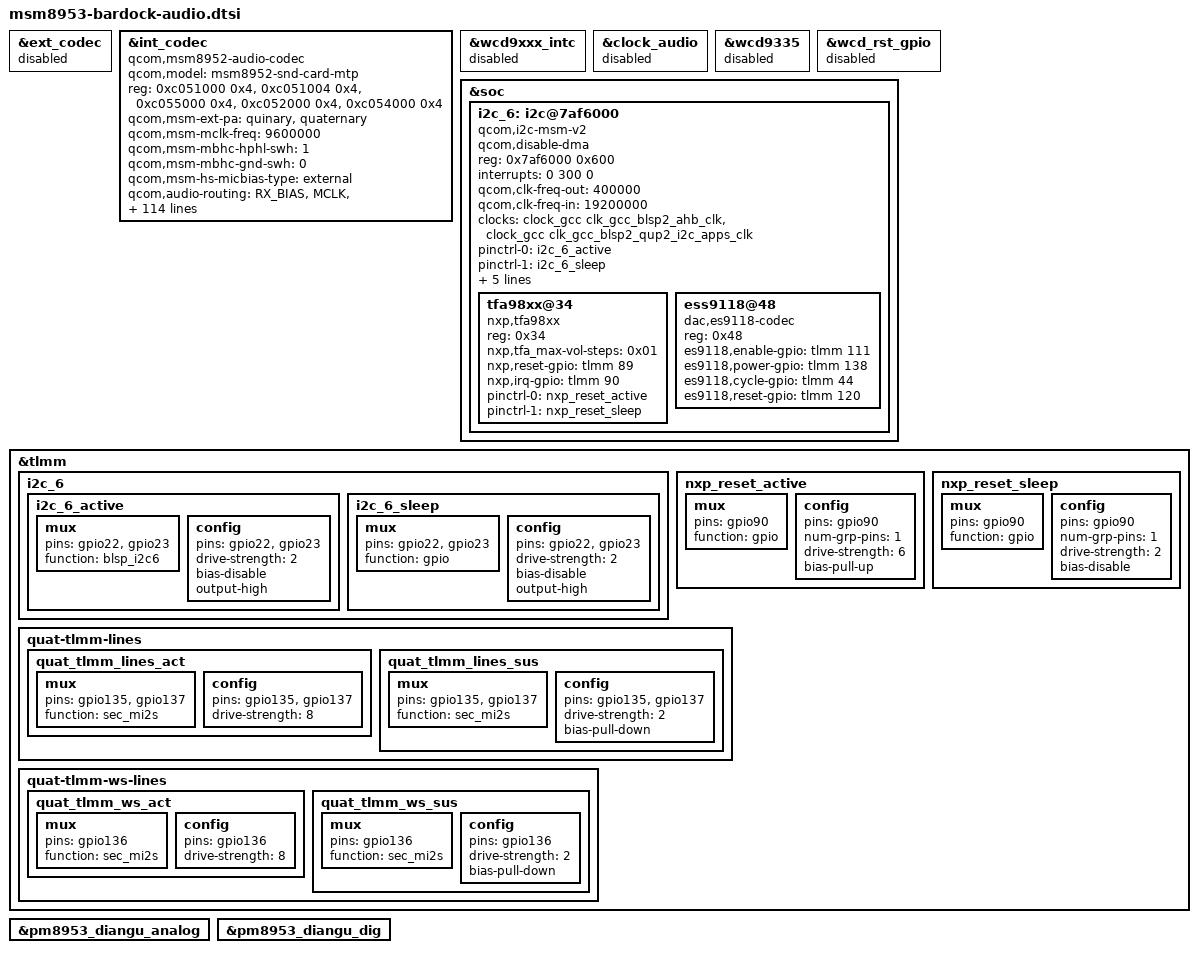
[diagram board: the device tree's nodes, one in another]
/*
 * Copyright (c) 2018, The LineageOS Project. All rights reserved.
 *
 * This program is free software; you can redistribute it and/or modify
 * it under the terms of the GNU General Public License version 2 and
 * only version 2 as published by the Free Software Foundation.
 *
 * This program is distributed in the hope that it will be useful,
 * but WITHOUT ANY WARRANTY; without even the implied warranty of
 * MERCHANTABILITY or FITNESS FOR A PARTICULAR PURPOSE.  See the
 * GNU General Public License for more details.
 */

&ext_codec {
	status = "disabled";
};

&int_codec {
	status = "ok";
	compatible = "qcom,msm8952-audio-codec";
	qcom,model = "msm8952-snd-card-mtp";

	/delete-property/ qcom,cdc-us-euro-gpios;

	reg =   <0xc051000 0x4>,
		<0xc051004 0x4>,
		<0xc055000 0x4>,
		<0xc052000 0x4>,
		<0xc054000 0x4>;
	reg-names = "csr_gp_io_mux_mic_ctl",
		"csr_gp_io_mux_spkr_ctl",
		"csr_gp_io_lpaif_pri_pcm_pri_mode_muxsel",
		"csr_gp_io_mux_quin_ctl",
		"csr_gp_io_mux_mic_ext_clk_ctl";

	qcom,msm-ext-pa = "quinary","quaternary";
	qcom,msm-mclk-freq = <9600000>;
	qcom,msm-mbhc-hphl-swh = <1>;
	qcom,msm-mbhc-gnd-swh = <0>;
	qcom,msm-hs-micbias-type = "external";

	qcom,audio-routing =
		"RX_BIAS", "MCLK",
		"SPK_RX_BIAS", "MCLK",
		"INT_LDO_H", "MCLK",
		"MIC BIAS External", "Handset Mic",
		"MIC BIAS External2", "Headset Mic",
		"MIC BIAS External", "Secondary Mic",
		"AMIC1", "MIC BIAS External",
		"AMIC2", "MIC BIAS External2",
		"AMIC3", "MIC BIAS External";
	qcom,msm-gpios = 
		"pri_i2s", 
		"us_eu_gpio", 
		"quin_i2s", 
		"quat_i2s"; 
	qcom,pinctrl-names = 
		"all_off", 
		"pri_i2s_act", 
		"us_eu_gpio_act", 
		"pri_i2s_us_eu_gpio_act", 
		"quin_act", 
		"quin_pri_i2s_act", 
		"quin_us_eu_gpio_act", 
		"quin_us_eu_gpio_pri_i2s_act", 
		"quat_i2s_act", 
		"quat_pri_i2s_act", 
		"quat_us_eu_gpio_act", 
		"quat_pri_i2s_us_eu_gpio_act", 
		"quat_quin_act", 
		"quat_quin_pri_i2s_act", 
		"quat_quin_us_eu_gpio_act", 
		"quat_quin_us_eu_gpio_pri_i2s_act"; 
	pinctrl-names = 
		"all_off", 
		"pri_i2s_act", 
		"us_eu_gpio_act", 
		"pri_i2s_us_eu_gpio_act", 
		"quin_act", 
		"quin_pri_i2s_act", 
		"quin_us_eu_gpio_act", 
		"quin_us_eu_gpio_pri_i2s_act", 
		"quat_i2s_act", 
		"quat_pri_i2s_act", 
		"quat_us_eu_gpio_act", 
		"quat_pri_i2s_us_eu_gpio_act", 
		"quat_quin_act", 
		"quat_quin_pri_i2s_act", 
		"quat_quin_us_eu_gpio_act", 
		"quat_quin_us_eu_gpio_pri_i2s_act"; 
	pinctrl-0 = <&cdc_pdm_lines_sus
			&quat_tlmm_lines_sus &quat_tlmm_ws_sus
			&cdc_pdm_lines_2_sus &cross_conn_det_sus 
			&pri_tlmm_lines_sus &pri_tlmm_ws_sus>; 
	pinctrl-1 = <&cdc_pdm_lines_act
			&quat_tlmm_lines_sus &quat_tlmm_ws_sus
			&cdc_pdm_lines_2_act &cross_conn_det_sus 
			&pri_tlmm_lines_sus &pri_tlmm_ws_sus>; 
	pinctrl-2 = <&cdc_pdm_lines_sus
			&quat_tlmm_lines_sus &quat_tlmm_ws_sus 
			&cdc_pdm_lines_2_sus &cross_conn_det_act 
			&pri_tlmm_lines_sus &pri_tlmm_ws_sus>; 
	pinctrl-3 = <&cdc_pdm_lines_act
			&quat_tlmm_lines_sus &quat_tlmm_ws_sus 
			&cdc_pdm_lines_2_act &cross_conn_det_act 
			&pri_tlmm_lines_sus &pri_tlmm_ws_sus>; 
	pinctrl-4 = <&cdc_pdm_lines_sus
			&quat_tlmm_lines_sus &quat_tlmm_ws_sus
			&cdc_pdm_lines_2_sus &cross_conn_det_sus 
			&pri_tlmm_lines_act &pri_tlmm_ws_act>; 
	pinctrl-5 = <&cdc_pdm_lines_act
			&quat_tlmm_lines_sus &quat_tlmm_ws_sus
			&cdc_pdm_lines_2_act &cross_conn_det_sus 
			&pri_tlmm_lines_act &pri_tlmm_ws_act>; 
	pinctrl-6 = <&cdc_pdm_lines_sus
			&quat_tlmm_lines_sus &quat_tlmm_ws_sus
			&cdc_pdm_lines_2_sus &cross_conn_det_act 
			&pri_tlmm_lines_act &pri_tlmm_ws_act>; 
	pinctrl-7 = <&cdc_pdm_lines_act
			&quat_tlmm_lines_sus &quat_tlmm_ws_sus
			&cdc_pdm_lines_2_act &cross_conn_det_act 
			&pri_tlmm_lines_act &pri_tlmm_ws_act>; 
	pinctrl-8 = <&cdc_pdm_lines_sus 
			&quat_tlmm_lines_act &quat_tlmm_ws_act
			&cdc_pdm_lines_2_sus &cross_conn_det_sus 
			&pri_tlmm_lines_sus &pri_tlmm_ws_sus>; 
	pinctrl-9 = <&cdc_pdm_lines_act 
			&quat_tlmm_lines_act &quat_tlmm_ws_act
			&cdc_pdm_lines_2_act &cross_conn_det_sus 
			&pri_tlmm_lines_sus &pri_tlmm_ws_sus>; 
	pinctrl-10 = <&cdc_pdm_lines_sus 
			&quat_tlmm_lines_act &quat_tlmm_ws_act
			&cdc_pdm_lines_2_sus &cross_conn_det_act 
			&pri_tlmm_lines_sus &pri_tlmm_ws_sus>; 
	pinctrl-11 = <&cdc_pdm_lines_act 
			&quat_tlmm_lines_act &quat_tlmm_ws_act
			&cdc_pdm_lines_2_act &cross_conn_det_act 
			&pri_tlmm_lines_sus &pri_tlmm_ws_sus>; 
	pinctrl-12 = <&cdc_pdm_lines_sus 
			&quat_tlmm_lines_act &quat_tlmm_ws_act
			&cdc_pdm_lines_2_sus &cross_conn_det_sus 
			&pri_tlmm_lines_act &pri_tlmm_ws_act>; 
	pinctrl-13 = <&cdc_pdm_lines_act 
			&quat_tlmm_lines_act &quat_tlmm_ws_act
			&cdc_pdm_lines_2_act &cross_conn_det_sus 
			&pri_tlmm_lines_act &pri_tlmm_ws_act>; 
	pinctrl-14 = <&cdc_pdm_lines_sus
			&quat_tlmm_lines_act &quat_tlmm_ws_act
			&cdc_pdm_lines_2_sus &cross_conn_det_act 
			&pri_tlmm_lines_act &pri_tlmm_ws_act>; 
	pinctrl-15 = <&cdc_pdm_lines_act
			&quat_tlmm_lines_act &quat_tlmm_ws_act
			&cdc_pdm_lines_2_act &cross_conn_det_act 
			&pri_tlmm_lines_act &pri_tlmm_ws_act>; 

	asoc-platform = <&pcm0>, <&pcm1>, <&pcm2>, <&voip>, <&voice>,
		<&loopback>, <&compress>, <&hostless>,
		<&afe>, <&lsm>, <&routing>, <&lpa>;
	asoc-platform-names = "msm-pcm-dsp.0", "msm-pcm-dsp.1",
		"msm-pcm-dsp.2", "msm-voip-dsp",
		"msm-pcm-voice", "msm-pcm-loopback",
		"msm-compress-dsp", "msm-pcm-hostless",
		"msm-pcm-afe", "msm-lsm-client",
		"msm-pcm-routing", "msm-pcm-lpa";
	asoc-cpu = <&dai_pri_auxpcm>, <&dai_mi2s0>, <&dai_mi2s1>,
		<&dai_mi2s2>, <&dai_mi2s3>,
		<&dai_mi2s5>, <&dai_mi2s6>,
		<&sb_0_rx>, <&sb_0_tx>, <&sb_1_rx>, <&sb_1_tx>,
		<&sb_3_rx>, <&sb_3_tx>, <&sb_4_rx>, <&sb_4_tx>,
		<&bt_sco_rx>, <&bt_sco_tx>,
		<&int_fm_rx>, <&int_fm_tx>,
		<&afe_pcm_rx>, <&afe_pcm_tx>,
		<&afe_proxy_rx>, <&afe_proxy_tx>,
		<&incall_record_rx>, <&incall_record_tx>,
		<&incall_music_rx>, <&incall_music_2_rx>;
	asoc-cpu-names = "msm-dai-q6-auxpcm.1",
		"msm-dai-q6-mi2s.0", "msm-dai-q6-mi2s.1",
		"msm-dai-q6-mi2s.2", "msm-dai-q6-mi2s.3",
		"msm-dai-q6-mi2s.5", "msm-dai-q6-mi2s.6",
		"msm-dai-q6-dev.16384", "msm-dai-q6-dev.16385",
		"msm-dai-q6-dev.16386", "msm-dai-q6-dev.16387",
		"msm-dai-q6-dev.16390", "msm-dai-q6-dev.16391",
		"msm-dai-q6-dev.16392", "msm-dai-q6-dev.16393",
		"msm-dai-q6-dev.12288", "msm-dai-q6-dev.12289",
		"msm-dai-q6-dev.12292", "msm-dai-q6-dev.12293",
		"msm-dai-q6-dev.224", "msm-dai-q6-dev.225",
		"msm-dai-q6-dev.241", "msm-dai-q6-dev.240",
		"msm-dai-q6-dev.32771", "msm-dai-q6-dev.32772",
		"msm-dai-q6-dev.32773", "msm-dai-q6-dev.32770";

	/delete-property/ asoc-wsa-codec-names;
	/delete-property/ asoc-wsa-codec-prefixes;
};

&wcd9xxx_intc {
	status = "disabled";
};

&clock_audio {
	status = "disabled";
};

&wcd9335 {
	status = "disabled";
};

&wcd_rst_gpio {
	status = "disabled";
};

&soc {
	i2c_6: i2c@7af6000 { /* BLSP2 QUP2 */
		compatible = "qcom,i2c-msm-v2";
		qcom,disable-dma;
		#address-cells = <1>;
		#size-cells = <0>;
		reg-names = "qup_phys_addr";
		reg = <0x7af6000 0x600>;
		interrupt-names = "qup_irq";
		interrupts = <0 300 0>;
		qcom,clk-freq-out = <400000>;
		qcom,clk-freq-in  = <19200000>;
		clock-names = "iface_clk", "core_clk";
		clocks = <&clock_gcc clk_gcc_blsp2_ahb_clk>,
			<&clock_gcc clk_gcc_blsp2_qup2_i2c_apps_clk>;
		pinctrl-names = "i2c_active", "i2c_sleep";
		pinctrl-0 = <&i2c_6_active>;
		pinctrl-1 = <&i2c_6_sleep>;
		qcom,noise-rjct-scl = <0>;
		qcom,noise-rjct-sda = <0>;
		qcom,master-id = <84>;
		dmas = <&dma_blsp2 6 64 0x20000020 0x20>,
			<&dma_blsp2 7 32 0x20000020 0x20>;
		dma-names = "tx", "rx";
	};
};

&tlmm {
	i2c_6 {
		i2c_6_active: i2c_6_active {
			/* active state */
			mux {
				pins = "gpio22", "gpio23";
				function = "blsp_i2c6";
			};

			config {
				pins = "gpio22", "gpio23";
				drive-strength = <2>;
				bias-disable;
				output-high;
			};
		};

		i2c_6_sleep: i2c_6_sleep {
			/* suspended state */
			mux {
				pins = "gpio22", "gpio23";
				function = "gpio";
			};

			config {
				pins = "gpio22", "gpio23";
				drive-strength = <2>;
				bias-disable;
				output-high;
			};
		};
	};
	nxp_reset_active: nxp_reset_active {
		mux {
			pins = "gpio90";
			function =  "gpio";
		};
		config {
			pins = "gpio90";
			num-grp-pins = <1>;
			drive-strength = <6>;
			bias-pull-up;
		};
	};
	nxp_reset_sleep: nxp_reset_sleep {
		mux {
			pins = "gpio90";
			function =  "gpio";
		};
		config {
			pins = "gpio90";
			num-grp-pins = <1>;
			drive-strength = <2>;
			bias-disable;
		};
	};
		
	quat-tlmm-lines {
		quat_tlmm_lines_act: quat_tlmm_lines_act {
			mux {
				pins = "gpio135", "gpio137";
				function = "sec_mi2s";
			};

			config {
				pins = "gpio135", "gpio137";
				drive-strength = <8>;
			};
		};

		quat_tlmm_lines_sus: quat_tlmm_lines_sus {
			mux {
				pins = "gpio135", "gpio137";
				function = "sec_mi2s";
			};

			config {
				pins = "gpio135", "gpio137";
				drive-strength = <2>;
				bias-pull-down;
			};
		};
	};

	quat-tlmm-ws-lines {
		quat_tlmm_ws_act: quat_tlmm_ws_act {
			mux {
				pins = "gpio136";
				function = "sec_mi2s";
			};

			config {
				pins = "gpio136";
				drive-strength = <8>;
			};
		};

		quat_tlmm_ws_sus: quat_tlmm_ws_sus {
			mux {
				pins = "gpio136";
				function = "sec_mi2s";
			};
			config {
				pins = "gpio136";
				drive-strength = <2>;
				bias-pull-down;
			};
		};
	};
};

&i2c_6 {
	tfa98xx@34 {
		compatible = "nxp,tfa98xx";
		//reg = <0x36>;
		reg = <0x34>;
		nxp,tfa_max-vol-steps=<0x01>;
		nxp,reset-gpio = <&tlmm 89 0>;
		nxp,irq-gpio = <&tlmm 90 0x2008>;
		pinctrl-names = "nxp_reset_active","nxp_reset_suspend";
		pinctrl-0 = <&nxp_reset_active>;
		pinctrl-1 = <&nxp_reset_sleep>;
		//Vdd-supply = <&pm8916_l6>;// only for test in 9100
		status = "okay";
	};
			
	ess9118@48 {
		status = "okay";
		compatible = "dac,es9118-codec";
		reg = <0x48>;
		es9118,enable-gpio = <&tlmm 111 0>;
		es9118,power-gpio = <&tlmm 138 0>;
		es9118,cycle-gpio = <&tlmm 44 0>;
		//es9118,power-gpio = <&tlmm 44 0>;
		//es9118,cycle-gpio = <&tlmm 138 0>;
		es9118,reset-gpio = <&tlmm 120 0>;
	};
};

&pm8953_diangu_analog {
	status = "ok";
};

&pm8953_diangu_dig {
        status = "ok";
};
